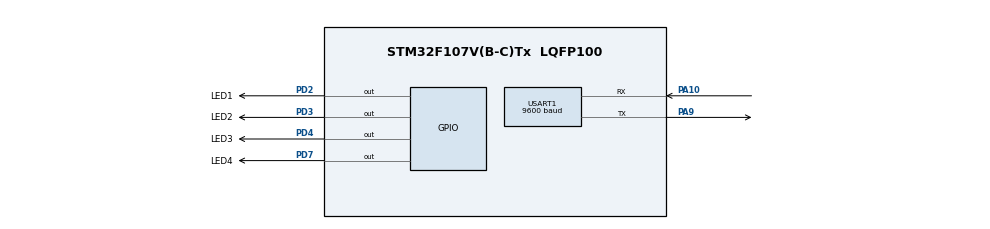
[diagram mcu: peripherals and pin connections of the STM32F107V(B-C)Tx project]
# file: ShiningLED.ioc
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Mcu.Family=STM32F1
Mcu.Name=STM32F107V(B-C)Tx
Mcu.Package=LQFP100
NVIC.PriorityGroup=NVIC_PRIORITYGROUP_4
PA10.Mode=Asynchronous
PA10.Signal=USART1_RX
PA9.Mode=Asynchronous
PA9.Signal=USART1_TX
PD2.GPIO_Label=LED1
PD2.Signal=GPIO_Output
PD3.GPIO_Label=LED2
PD3.Signal=GPIO_Output
PD4.GPIO_Label=LED3
PD4.Signal=GPIO_Output
PD7.GPIO_Label=LED4
PD7.Signal=GPIO_Output
ProjectManager.HeapSize=0x200
ProjectManager.StackSize=0x400
ProjectManager.TargetToolchain=MDK-ARM V5
RCC.USBFreq_Value=10666666.666666666
USART1.BaudRate=9600
USART1.VirtualMode=VM_ASYNC
VP_SYS_VS_ND.Mode=No_Debug
board=custom

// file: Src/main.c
/* USER CODE BEGIN Header */
/**
  ******************************************************************************
  * @file           : main.c
  * @brief          : Main program body
  ******************************************************************************
  * @attention
  *
  * <h2><center>&copy; Copyright (c) 2021 STMicroelectronics.
  * All rights reserved.</center></h2>
  *
  * This software component is licensed by ST under BSD 3-Clause license,
  * the "License"; You may not use this file except in compliance with the
  * License. You may obtain a copy of the License at:
  *                        opensource.org/licenses/BSD-3-Clause
  *
  ******************************************************************************
  */
/* USER CODE END Header */

#include "main.h"
#include "usart.h"
#include "gpio.h"

/* USER CODE BEGIN Includes */
#include "log.h"
#include "led.h"
/* USER CODE END Includes */

void SystemClock_Config(void);

int main(void)
{

  /* MCU Configuration--------------------------------------------------------*/

  /* Reset of all peripherals, Initializes the Flash interface and the Systick. */
  HAL_Init();

  /* Configure the system clock */
  SystemClock_Config();

  /* Initialize all configured peripherals */
  MX_GPIO_Init();
  MX_USART1_UART_Init();
  /* USER CODE BEGIN 2 */
  log_info("init done");
  /* USER CODE END 2 */

  /* Infinite loop */
  while (1)
  {
    led_shine(1000);
  }
}

void SystemClock_Config(void)
{
  RCC_OscInitTypeDef RCC_OscInitStruct = {0};
  RCC_ClkInitTypeDef RCC_ClkInitStruct = {0};

  /** Initializes the CPU, AHB and APB busses clocks
  */
  RCC_OscInitStruct.OscillatorType = RCC_OSCILLATORTYPE_HSI;
  RCC_OscInitStruct.HSIState = RCC_HSI_ON;
  RCC_OscInitStruct.HSICalibrationValue = RCC_HSICALIBRATION_DEFAULT;
  RCC_OscInitStruct.PLL.PLLState = RCC_PLL_NONE;
  RCC_OscInitStruct.PLL2.PLL2State = RCC_PLL_NONE;
  if (HAL_RCC_OscConfig(&RCC_OscInitStruct) != HAL_OK)
  {
    Error_Handler();
  }
  /** Initializes the CPU, AHB and APB busses clocks
  */
  RCC_ClkInitStruct.ClockType = RCC_CLOCKTYPE_HCLK|RCC_CLOCKTYPE_SYSCLK
                              |RCC_CLOCKTYPE_PCLK1|RCC_CLOCKTYPE_PCLK2;
  RCC_ClkInitStruct.SYSCLKSource = RCC_SYSCLKSOURCE_HSI;
  RCC_ClkInitStruct.AHBCLKDivider = RCC_SYSCLK_DIV1;
  RCC_ClkInitStruct.APB1CLKDivider = RCC_HCLK_DIV1;
  RCC_ClkInitStruct.APB2CLKDivider = RCC_HCLK_DIV1;

  if (HAL_RCC_ClockConfig(&RCC_ClkInitStruct, FLASH_LATENCY_0) != HAL_OK)
  {
    Error_Handler();
  }
  /** Configure the Systick interrupt time
  */
  __HAL_RCC_PLLI2S_ENABLE();
}

void Error_Handler(void)
{
}

/************************ (C) COPYRIGHT STMicroelectronics *****END OF FILE****/
